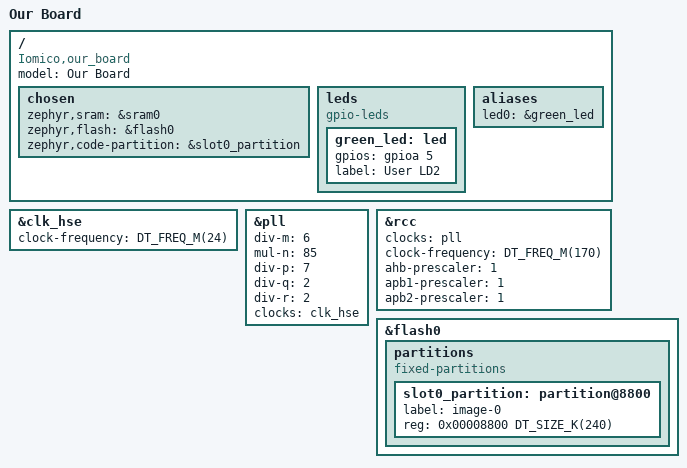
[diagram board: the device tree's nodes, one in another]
/*
 * Copyright (c) 2019 STMicroelectronics.
 *
 * SPDX-License-Identifier: Apache-2.0
 */

/dts-v1/;
#include <st/g4/stm32g474Xe.dtsi>
#include <st/g4/stm32g474r(b-c-e)tx-pinctrl.dtsi>
#include <zephyr/dt-bindings/input/input-event-codes.h>

/ {
	model = "Our Board";
	compatible = "Iomico,our_board";

	chosen {
		zephyr,sram = &sram0;
		zephyr,flash = &flash0;
		zephyr,code-partition = &slot0_partition;
	};

        leds: leds {
                compatible = "gpio-leds";

                green_led: led {
                        gpios = <&gpioa 5 GPIO_ACTIVE_HIGH>;
                        label = "User LD2";
                };
        };

        aliases {
                led0 = &green_led;
        };

};




&clk_hse {
	clock-frequency = <DT_FREQ_M(24)>;
	status = "okay";
};

&pll {
	div-m = <6>;
	mul-n = <85>;
	div-p = <7>;
	div-q = <2>;
	div-r = <2>;
	clocks = <&clk_hse>;
	status = "okay";
};

&rcc {
	clocks = <&pll>;
	clock-frequency = <DT_FREQ_M(170)>;
	ahb-prescaler = <1>;
	apb1-prescaler = <1>;
	apb2-prescaler = <1>;
};


&flash0 {
	partitions {
		compatible = "fixed-partitions";
		#address-cells = <1>;
		#size-cells = <1>;

		slot0_partition: partition@8800 {
			label = "image-0";
			reg = <0x00008800 DT_SIZE_K(240)>;
		};
	};
};

